# tviic2d4m register map
Vendor: Infineon Technologies; Series: TVIIC2D4M; File version: 1.0
CPU: CM7 r0p1, little endian, MPU, FPU, double-precision FPU, I-cache, D-cache, VTOR, ITCM, DTCM, 3 interrupt priority bits, 16 interrupts
Registers are 32-bit, read-write, reset 0x0 unless marked. A register's access mark holds for its fields unless they carry their own. Offsets are from the block's base; [hi:lo] are bit positions; lines under a group give offsets from that group; {n}, {i} and the like mark numbered series; <NAME> marks a mode.

## CXPI0 — CXPI
Base 0x40510000
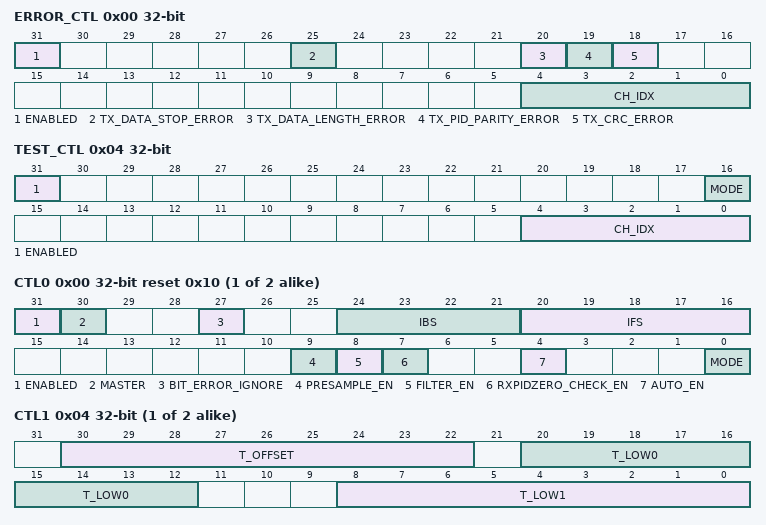
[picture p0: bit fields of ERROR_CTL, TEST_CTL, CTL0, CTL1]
0x00 ERROR_CTL — Error control
  [31] ENABLED — Error injection enable: '0': Disabled. '1': Enabled.
  [25] TX_DATA_STOP_ERROR — The data field STOP bits are inverted to '0'. At the receiver, this should result in INTR.RX_FRAME_ERROR activation. At the transmitter, this should result in INTR.TX_FRAME_ERROR activation.
  [20] TX_DATA_LENGTH_ERROR — The transmitter continues to send logical '0' (during IFS) after CRC field is transmitted. At the receiver, this should result in INTR.RX_DATA_LENGTH_ERROR activation. At the transmitter, this should result in INTR.TX_DATA_LENGTH_ERROR activation.
  [19] TX_PID_PARITY_ERROR — In cxpi mode, the PID parity bit P[1] is inverted from !(ID[5] ^ ID[4] ^ ID[3] ^ ID[1]) to (ID[5] ^ ID[4] ^ ID[3] ^ ID[1]). At the receiver, this should result in INTR.RX_HEADER_PARITY_ERROR activation.
  [18] TX_CRC_ERROR — The crc field is inverted. At the receiver, this should result in INTR.RX_CRC_ERROR activation.
  [4:0] CH_IDX — Specifies the channel index of the channel to which HW injected channel transmitter errors applies.
0x04 TEST_CTL — Test control
  [31] ENABLED — Test enable: '0': Disabled. Functional mode. - tx_in[CH_IDX] = IOSS cxpi_tx_in[CH_IDX]. - tx_in[CH_NR-1] = IOSS cxpi_tx_in[CH_NR-1]. - rx_in[CH_IDX] = IOSS cxpi_rx_in[CH_IDX]. - rx_in[CH_NR-1] = IOSS cxpi_rx_in[CH_NR-1]. - cxpi_tx_out[CH_IDX] = tx_out[CH_IDX]. - cxpi_tx_out[CH_NR-1] = tx_out[CH_NR-1]. '1': Enabled. Test mode, specific test mode is specified by MODE.
    0=FUNCTIONAL_MODE; 1=TEST_MODE
  [16] MODE — Test mode: '0': Partial disconnect from IOSS. This mode's isolation allows for device test without relying on an external cxpi transceiver. The IOSS 'tx' IO cell can be used to observe messages outside of the device. - tx_in[CH_IDX] = IOSS cxpi_tx_in[CH_IDX]. - tx_in[CH_NR-1] = IOSS cxpi_tx_in[CH_IDX]. - rx_in[CH_IDX] = IOSS cxpi_tx_in[CH_IDX]. - rx_in[CH_NR-1] = IOSS cxpi_tx_in[CH_IDX]. - cxpi_tx_out[CH_IDX] = tx_out[CH_IDX] & tx_out[CH_NR-1]. - cxpi_tx_out[CH_NR-1] = tx_out[CH_IDX] & tx_out[CH_NR-1]. '1': Full disconnect from IOSS (the IOSS/HSIOM should disconnect 'tx_out' from the 'tx' IO cell). This mode's isolation allows for device test without effecting an operational cxpi cluster. - tx_in[CH_IDX] = cxpi_tx_out[CH_IDX]. - tx_in[CH_NR-1] = cxpi_tx_out[CH_IDX]. - rx_in[CH_IDX] = cxpi_tx_out[CH_IDX]. - rx_in[CH_NR-1] = cxpi_tx_out[CH_IDX]. - cxpi_tx_out[CH_IDX] = tx_out[CH_IDX] & tx_out[CH_NR-1]. - cxpi_tx_out[CH_NR-1] = tx_out[CH_IDX] & tx_out[CH_NR-1].
    0=PARTIAL_DISCONNECT; 1=FULL_DISCONNECT
  [4:0] CH_IDX — Specifies the channel index of the channel to which test applies. The channel IO signals of channel indices CH_IDX and CH_NR-1 are connected as specified by MODE. CH_IDX should be in the range [0, CH_NR-2], as channel index CH_NR-1 is always involved in test and cannot be connected to itself. The test mode allows BOTH of the two connected channels to be tested. Note: this testing functionality simplifies SW development, but may also be used in the field to verify correct channel functionality.
{0x8000+0x100*i} CH[{i}] (i=0..1) group — CXPI channel structure
  0x00 CTL0 reset 0x10 — Control 0
    [31] ENABLED — Channel enable: '0': Disabled. If a channel is disabled, CMD, STATUS, INTR MMIO registers will have their fields reset to their default value. '1': Enabled.
      0=DISABLED; 1=ENABLED
    [30] MASTER — CXPI master mode. '0': Indicates CXPI as slave node. '1': Indicates CXPI as master node. This bit is only valid if ENABLED=1. SW needs to set only 1 node as master within the same CXPI cluster. SW needs to set this bit either at the same time as ENABLED or before ENABLED is set. If SW needs to change the controller to different mode, it needs to make sure that HW is quiescent before doing so.
      0=SLAVE_MODE; 1=MASTER_MODE
    [27] BIT_ERROR_IGNORE — Specifies behavior on a detected bit error during header or response transmission: '0': Message transfer is aborted. '1': Message transfer is NOT aborted. Note: This field does NOT effect the reporting of the bit error through INTR/STATUS.TX_BIT_ERROR; i.e. bit errors are always reported. Note: This field must not be set to '1' when it is NRZ mode. This is due to delay in transceiver will cause the transmitter behavior undefined when error occurs.
      0=ABORT_TX_MSG (Message transfer is aborted); 1=CONT_TX_MSG (Message transfer is NOT aborted)
    [24:21] IBS — Inter Byte Space in bit periods: '0' No offset. '1' 1 IBS is inserted per every byte frame. ... '9' 9 IBS are inserted per every byte frame. Values >9 are invalid per spec. This field is used to control number of IBS after every byte frame when transmitting message frame. Note that this field is the minimum IBS inserted for every byte frame as the SW may require some time to prepare the response when it receives the PID. When receiving, this field is ignored with the exception of receiving header and transmitting response. For receiving header and transmitting response, SW can enable IBS insertion by setting TIMEOUT_SEL=1/2 prior to setting CMD.RX_HEADER=1 and CMD.RX_RESPONSE=1. If the received header corresponds to transmit response, SW clears CMD.RX_RESPONSE =0 and sets TX FIFO and CMD.TX_RESPONSE=1. HW waits for minimum IBS before transmit response (if timeout has not occurred yet). It is prohibit to program IBS>TIMEOUT_LENGTH. This field should not be changed during inflight transaction including EOF.
    [20:16] IFS — Inter Frame Space in bit periods: '0'' Invalid. ... '10': 10 bit periods ... '31': 31 bit periods Values of <10 are not allowed. This field is used for transmission/reception for adding waiting inter frame space. Note that after a valid transaction (after CRC), HW waits for 10 bits as EOF. Hence, by setting CTL0.IFS=0xA means that HW will wait for 10bits before transmitting a new transaction (not including the EOF). Note: 0 is not allowed when IFS_WAIT=1. SW needs to ensure it has program valid values before it can set IFS_WAIT=1. If IFS_WAIT=1 after timeout occurs, the value of CTL0.IFS would need to consider the timeout count i.e. (IFS needed - CTL2.TIMEOUT_LENGTH-1) to get the total idle time. For example if TIMEOUT_LENGTH=9 and IFS needed is 20, then CTL0.IFS is set to 10.
    [9] PRESAMPLE_EN — Pre-sample enable for PWM mode. '0': Disbaled. '1': Enabled When sampling counter's value is greater than CTL1.T_LOW1, pre-sample FF will be set to '1' as long as detecting any '1' on 'cxpi_rx_in' and be cleared to '0' after sampling moment. At the sampling moment, if pre-sample FF or 'cxpi_rx_in' is '1', sample value will be '1', otherwise '0'.
    [8] FILTER_EN — RX filter enable (for 'cxpi_rx_in') '0': No filter '1': Median 3 (default value) operates on the last three 'cxpi_rx_in' values. The sequences '000', '001', '010', and '100' result in a filtered value '0'. The sequences '111', '110', '101', and '011' result in a filtered value '1'.
    [7] RXPIDZERO_CHECK_EN — Receive PID Zero Check Enable. 0 - No action if received PID[6:0] = 0 and PID[7]=1'b1. 1 - If received PID[6:0] = 0 and PID[7]=1'b1, HW (slave) does not clear CMD.RX_HEADER and will anticipate receiving header again (CMD.TX_HEADER=0). If CMD.TX_HEADER=1 in the same scenario, then HW (slave) clears CMD.RX_HEADER upon receiving the header follow by transmit PID. This mode is useful for case where polling method is used and CXPI controller is configured as slave. This would reduce dependency on SW to react to the header received within IBS=1.
    [4] AUTO_EN — CXPI transceiver auto enable: '0': Disabled. '1': Enabled. The TX_RX_STATUS.EN_OUT field is controlled by HW.
    [0] MODE — Mode of operation: '0': NRZ mode. '1': PWM mode.
      0=NRZ (NRZ mode); 1=PWM (PWM mode)
  0x04 CTL1 — Control 1
    [30:22] T_OFFSET — The value of offset that is used for sampling the 'rx'. The value of this counter is used in HW as below. - 0 : means 1 clock after detecting falling edge of 'rx' - 1 : means 2 clocks after detecting falling edge of 'rx' .. - 7 : means 8 clocks after detecting falling edge of 'rx' .. - 15 : means 16 clocks after detecting falling edge of 'rx' .. - 399 : means 400 clocks after detecting falling edge of 'rx' Any value above 399 is invalid.
    [20:12] T_LOW0 — Low count for logic 0. This is valid only for PWM mode. The count value here indicates the number of clocks per clk_cxpi_ch to drive a '0' at CXPI bus before releasing it to indicate a logical '0'. 0: means 1 clock. 1: means 2 clocks .. 15: means 16 clocks .. 399: means 400 clocks Any value above 399 is invalid. Note that for NRZ mode, this field is ignored. Note that this field is used for TX.
    [8:0] T_LOW1 — Low count for logic 1. This is valid only for PWM mode. For master node, The count value here indicates the number of clocks per clk_cxpi_ch to drive a '0' at CXPI bus before releasing it to indicate a logical '1'. For slave node and pre-sample enabled, the count value indicates the number of clocks per clk_cxpi_ch to disable pre-sampling. 0: means 1 clock. 1: means 2 clocks .. 15: means 16 clocks. .. 399: means 400 clocks. Any value above 399 is invalid. Note that for NRZ mode, this field is ignored. Note that it must be set less than CTL1.T_OFFSET for slave node if pre-sample mode enabled. Note that it is also effective for pre-sample mode of master node.
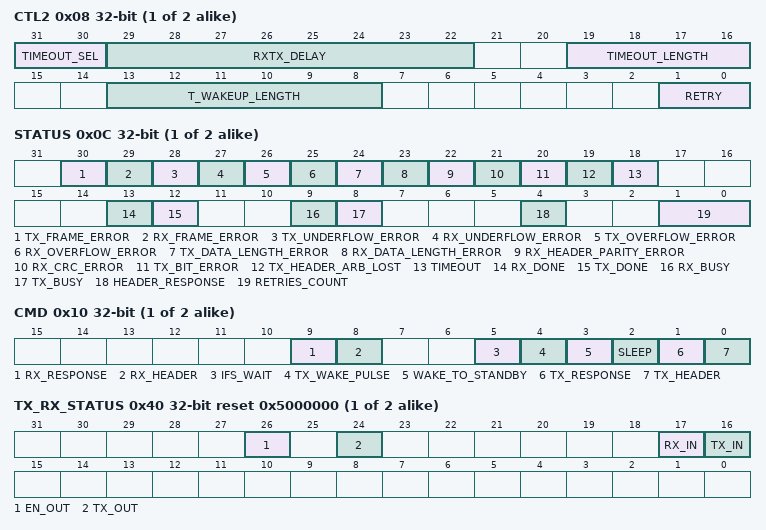
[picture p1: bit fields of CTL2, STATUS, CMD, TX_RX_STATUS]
  0x08 CTL2 — Control 2
    [31:30] TIMEOUT_SEL — Timeout Select. '0' - Timeout check is disabled. HW clears timeout counter. '1' - Timeout check is enabled and HW will refer to TIMEOUT_LENGTH as number of Tbits allowed between header and response. '2' - Timeout check is enabled to check header-header, header-response, and header-header-response within a message frame to be space within TIMEOUT_LENGTH bit time. '3' - invalid For '1', HW will restart/start timeout counter after transmitting/receiving header. HW will hold the counter if timeout until the next header is transmitted or received. Timeout will cause HW to stop transmission of the current message frame together with interrupt to SW. For receive, HW abort reception of the frame if timeout occurs while waiting for receiving response and notify SW with interrupt. For '2', HW will re-start/start timeout counter after receiving any frame bytes within a message frame. HW will hold the counter if timeout until the IFS. Timeout will cause HW to stop transmission of the current message frame and notify SW with interrupt. For receive, HW will abort reception of the message frame if timeout occurs while waiting for receiving response and notify SW with interrupt. For all cases, HW stops counting when it is out of a message frame such as IFS or CXPI bus IDLE. If the timeout counter > TIMEOUT_LENGTH, then it will set the INTR.TIMEOUT=1. Note that, TIMEOUT_SEL=1/2 also enables the count for IBS between receive header and transmit response on top of timeout check.
      0=TIMEOUT_DISABLED (Timeout check is disabled.); 1=TIMEOUT_CHECK_BTW_HDR_RSP (Timeout check is enabled and HW will refer to TIMEOUT_LENGHT as number of Tbits allowed between header and response.); 2=TIMEOUT_CHECK_BTW_HDR_HDR_RSP (Timeout check is enabled to check header-header, header-response, and header-header-response within a message frame to be space within TIMEOUT_LENGTH bit time.)
    [29:22] RXTX_DELAY — Insert addtional delay from the falling edge of RX to the falling edge of TX for slave node transmitting '0'. This is valid only for PWM mode. The count value here indicates the number of clocks per clk_cxpi_ch. 0: None 1: means 1 clock. 2: means 2 clocks. ... 255: means 255 clocks. Note it must be set less than CTL1.T_LOW0. Note make sure that the falling edge of tx_out is ahead of the rising edge of master node clock when CTL0.PRESAMPLE_EN=1.
    [19:16] TIMEOUT_LENGTH — Timeout Length (in Tbits). Specifies the number of Tbits to exceed timeout between frame bytes within a message frame. CXPI spec states that the maximum allowed inter byte space (IBS) is 9Tbits. This field is valid only when TIMEOUT_SEL=1/2. '0' - 1Tbit '1' - 2Tbits .. '9' - 10Tbits Values >9 is invalid per CXPI spec. Note for NRZ mode, although there are propagation delay from transceiver to CXPI controller, the delay is cancelled out as the timeout is compared on the RX (for transmit case, HW waits for the feedback on RX).
    [13:8] T_WAKEUP_LENGTH — Specifies the wake up pulse low period in Tbits that is transmitted during Standby mode. '0': 1 bit period '1': 2 bit period .. '49': 50 bit period Any value above 49 is invalid. This field is only valid if TX_WAKE_PULSE is set to 1.
    [1:0] RETRY — Number of retries after arbitration lost. '0': No retries. .. '3': 3 retries. HW will immediately retry after arbitration lost i.e. after the message frame that won the arbitration is complete and fulfilled IFS. If SW wants to manage the retransmission then SW can program RETRY =0. In this case, HW will not retry after arbitration lost and will set TX_HEADER_ARB_LOST bit. SW needs to trigger HW to resend by programming the CMD fields again.
  0x0C STATUS ro
    [30] TX_FRAME_ERROR — Copy of INTR.TX_FRAME_ERROR.
    [29] RX_FRAME_ERROR — Copy of INTR.RX_FRAME_ERROR.
    [28] TX_UNDERFLOW_ERROR — Copy of INTR.TX_UNDERFLOW_ERROR.
    [27] RX_UNDERFLOW_ERROR — Copy of INTR.RX_UNDERFLOW_ERROR.
    [26] TX_OVERFLOW_ERROR — Copy of INTR.TX_OVERFLOW_ERROR.
    [25] RX_OVERFLOW_ERROR — Copy of INTR.RX_OVERFLOW_ERROR.
    [24] TX_DATA_LENGTH_ERROR — Copy of INTR.TX_DATA_LENGTH_ERROR.
    [23] RX_DATA_LENGTH_ERROR — Copy of INTR.RX_DATA_LENGTH_ERROR.
    [22] RX_HEADER_PARITY_ERROR — Copy of INTR.RX_HEADER_PARITY_ERROR.
    [21] RX_CRC_ERROR — Copy of INTR.RX_CRC_ERROR.
    [20] TX_BIT_ERROR — Copy of INTR.TX_BIT_ERROR.
    [19] TX_HEADER_ARB_LOST — Copy of INTR.TX_HEADER_ARB_LOST
    [18] TIMEOUT — Copy of INTR.TIMEOUT
    [13] RX_DONE — Receiver done: - Set to '0' on the start of a new command. - Set to '1' on successful completion of the following commmand sequences: - RX_HEADER, RX_RESPONSE. - TX_HEADER, RX_RESPONSE.
    [12] TX_DONE — Transmitter done: - Set to '0' on the start of a new command. - Set to '1' on successful completion of the following command sequences: - TX_HEADER. - TX_HEADER, TX_RESPONSE. - RX_HEADER, TX_RESPONSE.
    [9] RX_BUSY — Receiver busy. - Set to '1' on the start of the following commands: RX_HEADER, RX_RESPONSE. - Set to '0' on successful completion of previous commands or when an error is detected.
    [8] TX_BUSY — Transmitter busy. - Set to '1' on the start of the following commands: TX_HEADER, TX_RESPONSE. - Set to '0' on successful completion of previous commands or when an error is detected.
    [4] HEADER_RESPONSE — Frame header/response identifier (only valid when TX_BUSY or RX_BUSY is '1') '0' - Frame header being transferred. '1' - Frame response being transferred.
    [1:0] RETRIES_COUNT — Retries count. The value reflects the number of retries that HW tries to transmit a header/response. HW will reset counter (either case below): 1. after successfully transmit the retry attempt 2. SW clears the CMD.TX_HEADER='0' 3. HW clearing CMD.TX_HEADER=0 due to errors (TX_BIT_ERROR, TX_HEADER_ARB_LOST, TX_OVERFLOW_ERROR, TX_UNDERFLOW_ERROR, TX_DATA_LENGTH_ERROR, and TX_FRAME_ERROR)
  0x10 CMD — Command
    [9] RX_RESPONSE — SW sets this field to '1' to receive a response. HW sets this field to '0' on successful completion of ANY of the legal command sequences (NOT set to '0' when an error is detected). -TX_HEADER, RX_RESPONSE -RX_HEADER, RX_RESPONSE SW can set this field to '1' to be conservative on receiving response i.e. IBS=0 whenever it is receiving PID. If the PID corresponds to transmit response, the SW can then clear this field to '0' and set TX_RESPONSE=1 to direct HW to send response. The response is received after CRC are received (INTR.RX_RESPONSE_DONE).
    [8] RX_HEADER — SW sets this field to '1' to receive a header. HW sets this field to '0' on successful completion of the ANY of the legal command sequences. (Not set to '0' when an error is detected). -RX_HEADER -RX_HEADER, TX_RESPONSE -RX_HEADER, RX_RESPONSE The above applies for cases of receiving PID without prior receiving PTYPE. The header is received when the PID field STOP bits are received (INTR.RX_HEADER_PID_DONE and INTR.RX_HEADER_DONE). Typically, a slave node SW sets both RX_HEADER and RX_RESPONSE to '1', anticipating a transfer of a response from the master node to this slave node. After receipt of the header PID/PTYPE field (INTR.RX_HEADER_PID_DONE is activated), the slave node may decide to set TX_RESPONSE to '1' (which has lower priority than RX_RESPONSE hence RX_RESPONSE need to be clear to '0' by SW) to transmit a response. Note that, for cases with RXPIDZERO_CHECK_EN=1 for slave in polling mode, RX_HEADER is cleared upon receiving PTYPE if the next course of action is to transmit PID. If the next course of action is to receive PID, then the RX_HEADER is cleared upon completion of response.
    [5] IFS_WAIT — SW sets this field to '1' to wait for IFS. HW clears this field to '0' after it detects logical '1' based on IFS. HW will keep this field to '1' if it detects logical '0' before fulfilling the number of logical '1' required. The intention of this bit is to provide capability for SW to direct HW to check bus idle-ness before transmitting. Without setting this bit before directing HW to send header, HW will not check bus idle before transmitting. Besides that, this bit will also provide SW an option to configure HW to wait for IFS before sending again PTYPE or PID to fulfill IFS if there is no response from other nodes. Note: SW needs to configure valid IFS values before setting IFS_WAIT=1.
    [4] TX_WAKE_PULSE — SW sets this field to '1' to direct HW to send wake up pulse. HW will transmit wake up pulse in Standby state only. HW will ignore this field when it's not in Standby state. '1' - HW will drive CXPI bus to low for period dictated by T_WAKEUP_LENGTH. '0:'- No wake up pulse HW clears this field to '0' after it transmit the pulse per T_WAKEUP_LENGTH. For the case where more than 1 wake pulses are required, SW is expected to set this field to '1' again (after this field is cleared to '0') per the number of times the wake pulse is required.
    [3] WAKE_TO_STANDBY — SW sets this field to '1' to direct HW to wake up from Sleep mode to Standby mode. SW clears this field to '0' from '1' when it wants to direct HW from Standby to Normal mode. HW clears this field to '0' when it is in Normal mode or back to Sleep mode from Standby mode. For the case of CXPI master mode, HW will move its power mode from Sleep->Standby when this field is set to '1'. When SW clears this field is from '1' to '0' in Standby mode, HW will move to Normal mode while HW starts transmitting clock. To transmit wake pulse, SW need to program TX_WAKE_PULSE accordingly in Standby mode before entering Normal. For the case of CXPI slave mode and PWM mode, HW will move power mode from Sleep->Standby when this field is set to '1'. HW will wait for detection of clock before moving from Standby->Normal. SW clearing this field to '0' will have no effect. For the case of CXPI slave mode and NRZ mode, HW will move power mode from Sleep->Standby when this field is set to '1'. HW needs to be directed by SW by clearing this field to '0' to move from Standby->Normal after SW has detected clock through another IP (e.g. MXTCPWM).
    [2] SLEEP write-1-sets — SW sets this field to '1' to direct HW to sleep mode. HW transits from Normal to Sleep upon SLEEP=1 and both TX and RX is idle. HW sets this field to '0' when it is in Sleep mode. Note that, SW needs to manage the entry to sleep mode by checking the conditions are met before initiating sleep mode e.g. all slave nodes supports sleep and on transmitting sleep frames to indicate sleep to all slave nodes.SW shall not program SLEEP=1 when HW is executing TX_WAKEUP_PULSE command. If SW programs SLEEP=1 during HW executing TX_WAKEUP_PULSE command, it will cause HW to abruptly stop transmitting wakeup pulse as below: 1. HW not clearing TX_WAKEUP_PULSE 2. HW not setting TX_WAKEUP_DONE 3. HW outputting TX_OUT=0.
    [1] TX_RESPONSE — SW sets this field to '1' to transmit a response. HW sets this field to '0' on successful completion of ANY of the legal command sequences (also set to '0' when an error is detected). - TX_HEADER, TX_RESPONSE. - RX_HEADER, TX_RESPONSE. SW can also clear this field to '0' if SW wants to cancel the TX_RESPONSE. The response is transmitted when the CRC are transmitted (INTR.TX_RESPONSE_DONE).
    [0] TX_HEADER — SW sets this field to '1' to transmit a header. HW sets this field to '0' on successful completion of ANY of the following legal command sequences (also set to '0' when an error (such as bit error if bit_ignore=0, arbitration loss, tx data length error. For timeout please refer to SAS) is detected): - TX_HEADER - TX_HEADER, TX_RESPONSE. - TX_HEADER, RX_RESPONSE. The above is for transmission of PID without prior transmission of PTYPE. The header is transmitted when the PID field STOP bits are transmitted (INTR.TX_HEADER_DONE). HW sets this field to '1', when the 'tr_cmd_tx_header' input trigger is activated. This allows for time triggered CXPI message transfer. HW driven time triggered transfer eliminates the jitter that is typically associated with SW driven transfer. SW clears this field to '0', when it wants to cancel a pending request. Note that if SW clears this field to '0' while HW is already in the middle of the request, then the cancel will be ignored. The cancel request can happen when HW is pending a retry when it is still servicing the current transaction. Or the cancel request can occur when HW is checking IFS/bus idle-ness. Note that if PTYPE (TX_HEADER) is transmitted follow by receive response (RX_RESPONSE) or no response, HW clears TX_HEADER right after transmitting PTYPE.
  0x40 TX_RX_STATUS reset 0x5000000 (reset mask 0x5000000)
    [26] EN_OUT — CXPI transceiver enable ('en_out', 'cxpi_en_out'). This field controls the enable (or low active sleep enable) of the external transceiver: '0': Disabled. '1': Enabled. If CTL0.AUTO_EN is '0', SW controls this field to enable the external transceiver. If CTL0.AUTO_EN is '1', HW controls this field to enable the external transceiver: - HW sets this field to '1' when it is out of Sleep state. If it moves to Sleep state, HW will clear this field to '0'.
    [24] TX_OUT ro — CXPI transmitter output ('tx_out', 'cxpi_tx_out').
    [17] RX_IN ro — CXPI receiver input ('rx_in', 'cxpi_rx_in' in functional mode).
    [16] TX_IN ro — CXPI transmitter input ('tx_in', 'cxpi_tx_in' in functional mode). TX_IN and RX_IN can be used to determine a wakeup source. Note that wakeup source detection relies on the external transceiver functionality.
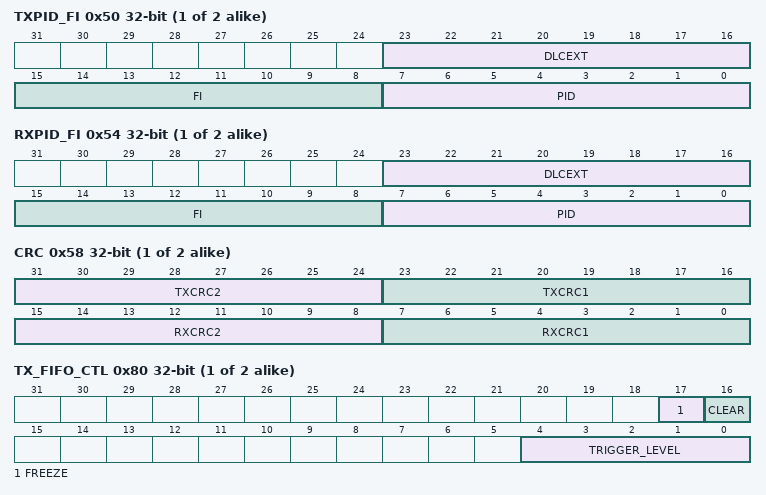
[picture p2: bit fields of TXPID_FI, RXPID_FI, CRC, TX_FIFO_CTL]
  0x50 TXPID_FI reset not defined — TXPID and Frame Information
    [23:16] DLCEXT — Data Length Count Extension. This field is intended for payload of more than 12B. This field is only valid if DLC=4'b1111 (FI[7:4]). The value specified in this field will be the new payload size. Valid values are 0-255.
    [15:8] FI — Frame Information. This is the byte that will be transmitted as Frame Information. Per CXPI spec, FI[7:4] denotes the data length count (DLC). FI[3:2] denotes Network Management. Bit[3] - wakeup.ind Bit[2] - sleep.ind FI[1:0] denotes CT. Please program to 2'b11 if no support of counter.
    [7:0] PID — Header protected identifier (PID). - Bits 6 downto 0: frame identifier ID[6:0]. - Bits 7: is odd parity bit. - PID[7] = ! (ID[6] ^ ID[5] ^ ID[4] ^ ID[3] ^ ID[2] ^ ID[1] ^ ID[0]) Software does not need to program the parity bit i.e. bit[7]. HW will calculate the odd parity bit and ignore the bit[7] if SW occupies this bit. Transmission: To be transmitted PID field. HW will ignore bit[7] and compute the parity bit based on bits[6:0] Note that, this field can be use by SW to send PType byte as the HW handles both PID and PType the same way. The frame type would occupy bit[6:0] and the odd parity will be calculated by the HW.
  0x54 RXPID_FI ro reset not defined — RXPID and Frame Information
    [23:16] DLCEXT — Data Length Count Extension. This field is intended for payload of more than 12B. This field is only valid if DLC=4'b1111 (FI[15:12]). The value specified in this field will be the new payload size. Valid values are 0-255.
    [15:8] FI — Frame Information. This is the byte that is received as Frame Information. Per CXPI spec, FI[7:4] denotes the data length count (DLC). FI[3:2] denotes Network Management. Bit[3] - wakeup.ind Bit[2] - sleep.ind FI[1:0] denotes CT.
    [7:0] PID — Header protected identifier (PID). - Bits 6 downto 0: frame identifier ID[6:0]. - Bits 7: is odd parity bit. - PID[7] = ! (ID[6] ^ ID[5] ^ ID[4] ^ ID[3] ^ ID[2] ^ ID[1] ^ ID[0]) Reception: Received PID field. SW uses the PID field to determine how to handle the response for a received frame header: TX_RESPONSE or RX_RESPONSE. Note that, this field can be use by SW to check PType byte as the HW handles both PID and PType the same way. The frame type would occupy bit[6:0] and bit[7] is the parity bit of the frame type. This parity bit is send by the transmitting node.
  0x58 CRC ro reset not defined
    [31:24] TXCRC2 — CRC second byte of CRC16. This is valid only for Long frames. HW will load this field with second byte of CRC for transmit.
    [23:16] TXCRC1 — CRC first byte for both CRC8 and CRC16. This is valid for both Normal frame and Long frame. HW will load this field with first byte of CRC for transmit.
    [15:8] RXCRC2 — CRC second byte of CRC16. This is valid only for Long frames. HW will load this field with second byte of CRC upon receiving it.
    [7:0] RXCRC1 — CRC first byte for both CRC8 and CRC16. This is valid for both Normal frame and Long frame. HW will load this field with first byte of CRC upon receiving it.
  0x80 TX_FIFO_CTL — TX FIFO control
    [17] FREEZE — Freeze functionality: '0': HW uses TX FIFO data and pops the data from the TX FIFO for every HW read. '1': HW read from TX FIFO does not pop the data from the TX FIFO. Note: Freeze functionality is for debug purpose only.
    [16] CLEAR — This is a synchronous clear signal to the TX FIFO. When '1', the TX FIFO content are cleared. If a quick clear is required, the field should be set to '1' and followed by '0'. If a clear is required for an extended time, the field should be set to 1 during the complete time.
    [4:0] TRIGGER_LEVEL — Trigger level. When the TX FIFO has less entries than the number of this field, a transmitter trigger event is generated: -INTR.TX_FIFO_TRIGGER = (#FIFO entries < TRIGGER_LEVEL)
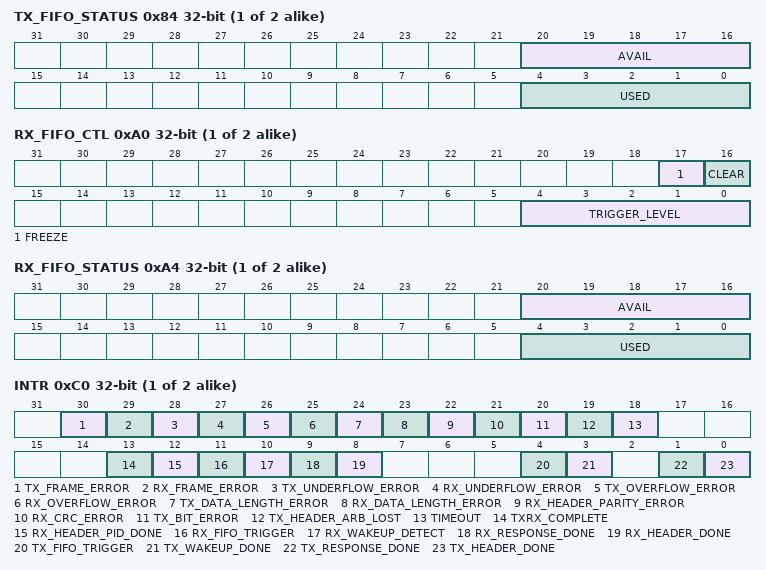
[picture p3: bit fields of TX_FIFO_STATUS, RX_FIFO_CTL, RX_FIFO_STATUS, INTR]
  0x84 TX_FIFO_STATUS ro (reset mask 0x1F)
    [20:16] AVAIL — TX FIFO Avail 0-No available slot in TX FIFO 1-1 available slot in TX FIFO. 2-2 available slot in TX FIFO. .. 16-16 available slot in TX FIFO. Note that the Fifo Width is 1Byte and each slot in this context is 1 depth of the Fifo. The number of bytes are determine through the number of data bytes in a message frame. (TXPID_FI.FI/TXPID_FI.DLCEXT)
    [4:0] USED — Number of used/occupied entries in the TX FIFO. The field value is in the range [0, 16]. When '0', the TX FIFO is empty. When '16', the TX FIFO is full.
  0x88 TX_FIFO_WR wo — TX FIFO write
    [7:0] DATA — Transmit Data field. Transmission: To be transmitted data field. SW provides data field. HW shadows over the write data to TX FIFO after SW performs a write to this field. HW shadows the whole 8 bits to the TX FIFO and relies on the TXPID_FI.FI/TXPID_FI.DCLEXT to determine the number of bytes. SW needs to ensure that TX FIFO is not overwritten before the content is consumed by HW by checking TX_FIFO_STATUS.AVAIL. Otherwise, the previous content would be overwritten and resulting in TX FIFO's overflow error (INTR.TX_OVERFLOW_ERROR).
  0xA0 RX_FIFO_CTL — RX FIFO control
    [17] FREEZE — Freeze functionality: '0': HW writes to RX FIFO and push the data to RX FIFO. '1': HW write to RX FIFO does not push the data to the RX FIFO. Note: Freeze functionality is for debug purpose only.
    [16] CLEAR — When '1', the RX FIFO content are popped. If a quick clear is required, the field should be set to '1' and followed by '0'. If a clear is required for an extended time, the field should be set to 1 during the complete time.
    [4:0] TRIGGER_LEVEL — Trigger level. When RX FIFO has more entries than the number of this field, a receiver trigger event is generated. - INTR_RX.FIFO_TRIGGER = (#FIFO entries > TRIGGER_LEVEL)
  0xA4 RX_FIFO_STATUS ro (reset mask 0x1F)
    [20:16] AVAIL — RX FIFO avail 0-No content in RX FIFO 1-1 available content in RX FIFO. 2-2 available content in RX FIFO. .. 16-16 available content in RX FIFO. Note that the Fifo Width is 1Byte and each content in this context means 1 fifo slot. The number of bytes in each slot are determine through the number of data bytes in a message frame. (RXPID_FI.FI/RXPID_FI.DLCEXT)
    [4:0] USED — Number of used/occupied entries in the RX FIFO. The field value is in the range [0, 16]. When '0', the RX FIFO is empty. When '16', the RX FIFO is full.
  0xA8 RX_FIFO_RD ro reset not defined — RX FIFO read
    [7:0] DATA — Received Data field. Software uses this data field. HW shadows the first content of the RX FIFO to this field. Software reading this field will remove the content from the RX FIFO and the next content of the RX FIFO will be shadowed over to this field. This field is 8bits and reflects the width of the RX FIFO. Software needs to rely on the RXPID_FI.FI/RXPID_FI.DLCEXT fields to determine number of bytes. Note that, during debug, a read from test controller would not remove/destory the content. Software needs to ensure it does not read from this field if there is no available content (from RX_FIFO_STATUS.USED). Otherwise, the content is undefined and it would result in RX FIFO underflow error. (INTR.RX_UNDERFLOW_ERROR).
  0xAC RX_FIFO_RD_SILENT ro reset not defined — RX FIFO silent read
    [7:0] DATA — Data read from the RX FIFO. Reading data from this field would not pop the data from RX FIFO. This register is for debug purpose.
  0xC0 INTR — Interrupt
    [30] TX_FRAME_ERROR write-1-clears — HW sets this field to '1', when the stop bit of a byte frame is incorrect. This error would be a subset of TX_BIT_ERROR and also subjected to BIT_ERROR_IGNORE field. Note: The ongoing message transfer is aborted (RX_HEADER_DONE and INTR.TX_RESPONSE_DONE are NOT activated. INTR.TX_HEADER_DONE is NOT activated if frame error occurs during the transmission of header byte) and the TX_HEADER and TX_RESPONSE commands are set to '0'. Note: When CTL0.BIT_ERROR_IGNORE is '0', the ongoing message transfer is aborted (INTR.TX_RESPONSE_DONE is NOT activated. INTR.TX_HEADER_DONE is NOT activated if frame error occurs during the transmission of header byte) and the TX_HEADER and TX_RESPONSE commands are set to '0'. When CTL0.BIT_ERROR_IGNORE is '1', the ongoing message transfer would be transferred.
    [29] RX_FRAME_ERROR write-1-clears — HW sets this field to '1', when the stop bit of a byte frame is incorrect. Note: The ongoing message transfer is aborted (INTR.RX_RESPONSE_DONE is NOT activated and the INTR.RX_HEADER_DONE is NOT activated if the frame error occurs during header byte or if frame error occurs during response byte (if the HEADER and RESPONSE commands are set together)).
    [28] TX_UNDERFLOW_ERROR write-1-clears — HW sets this field to '1', when TX FIFO is empty and HW reads from it. Note: The ongoing message transfer will continue when this error happens however, data transferred at CXPI will be bogus and HW will invert the CRC to invalidate the message at the receiving node. TX_HEADER and TX_RESPONSE commands are set to '0'.
    [27] RX_UNDERFLOW_ERROR write-1-clears — HW sets this field to '1', when RX FIFO is empty and SW reads from it. Note: Upon this error, SW should discard the RX data in RX FIFO.
    [26] TX_OVERFLOW_ERROR write-1-clears — HW sets this field to '1', when the TX data is overwritten by SW before the HW reads from it to transmit to CXPI bus. Note: The ongoing message transfer will continue when this error happens however, data transferred at CXPI bus will be bogus and HW will invert the CRC to invalidate the message at the receiving node. TX_HEADER and TX_RESPONSE commands are set to '0'.
    [25] RX_OVERFLOW_ERROR write-1-clears — HW sets this field to '1', when the RX data is overwritten by HW before the SW reads from it. In CXPI spec, this error is denoted as overrun error. Note: Upon this error, SW should discard the RX data in RX FIFO.
    [24] TX_DATA_LENGTH_ERROR write-1-clears — HW sets this field to '1, when the transmit message frame's data fields are more than the value specified in DLC (for normal frame) or DLCEXT (for long frame) i.e. after transmitting CRC(s) byte, HW is receiving logical '0' during EOF. Note: HW will still set TX_RESPONSE_DONE and the TX_HEADER and TX_RESPONSE commands are set to '0'.
    [23] RX_DATA_LENGTH_ERROR write-1-clears — HW sets this field to '1, when the received message frame's data fields are more than the value specified in DLC (for normal frame) or DLCEXT (for long frame) i.e. after receiving CRC byte(s), HW is receiving logical '0' during EOF. For the case of receiving data length less than DLC/DLCEXT, HW will also set this field to '1'. This is the case where IBS>9 before the number of data reaches data length, then HW will report as data length error. HW starts checking after frame information byte. Note: SW needs to handle the message transfer i.e. discard or flush out. HW will still set the RX_RESPONSE_DONE.
    [22] RX_HEADER_PARITY_ERROR write-1-clears — HW sets this field to '1', when the received PID field or PType field has a parity error. Note: The ongoing message transfer is aborted (INTR.RX_HEADER_PID_DONE is NOT activated).
    [21] RX_CRC_ERROR write-1-clears — HW sets this field to '1', when received CRC is not matching with the compute CRC from header and response. Note: The ongoing message transfer is aborted (INTR.RX_RESPONSE_DONE is NOT activated).
    [20] TX_BIT_ERROR write-1-clears — HW sets this field to '1', when a transmitted 'cxpi_tx_out' value does NOT match a received 'cxpi_rx_in' value. The match is performed for the PID fields or PType (for the START bit and STOP bit only) and for the rest of the response i.e. frame information fields, data fields and the crc field (for the START bit, DATA bits, and STOP bits). Note: When CTL0.BIT_ERROR_IGNORE is '0', the ongoing message transfer is aborted (INTR.TX_RESPONSE_DONE is NOT activated. INTR.TX_HEADER_DONE is NOT activated if bit error occurs during the transmission of header byte) and the TX_HEADER and TX_RESPONSE commands are set to '0'. When CTL0.BIT_ERROR_IGNORE is '1', the ongoing message transfer would be transferred.
    [19] TX_HEADER_ARB_LOST write-1-clears — HW sets this field to '1', when it detects arbitration lost after the number of retries has exceed the maximum allowed retries. Note: The ongoing message transfer is aborted (INTR.TX_HEADER_DONE and INTR.TX_RESPONSE_DONE is NOT activated and the TX_HEADER and TX_RESPONSE command is cleared to 0).
    [18] TIMEOUT write-1-clears — HW sets this field to '1', when the transmitted/received bytes space within a message frame is > TIMEOUT_LENGTH. SW needs to set TIMEOUT_SEL=0 before clearing TIMEOUT=0 to ensure HW does not immediately sets back the interrupt.
    [13] TXRX_COMPLETE write-1-clears — HW sets this field to '1', when message frame ends after EOF is completed and TX/RX_DATA_LENGTH_ERROR=0.
    [12] RX_HEADER_PID_DONE write-1-clears — HW sets this field to '1', when RX header (PID/PTYPE field) is received.
    [11] RX_FIFO_TRIGGER write-1-clears — HW sets this field to '1', when RX trigger is generated (#used RX FIFO > TRIGGER_LEVEL).
    [10] RX_WAKEUP_DETECT write-1-clears — HW sets this field to '1', when RX fall is detected in Sleep mode.
    [9] RX_RESPONSE_DONE write-1-clears — HW sets this field to '1', when a frame response (frame information fields, data fields, and crc field) is received (the CMD.RX_RESPONSE is completed).
    [8] RX_HEADER_DONE write-1-clears — HW sets this field to '1', when a frame header (PID field or PType field) is received (the CMD.RX_HEADER is completed). Specifically: - When followed by CMD.TX_RESPONSE or CMD.RX_RESPONSE, this field is set to '1' after completion of the message frame transfer. - When not followed by a response command, this field is set to '1' after completion of the header transfer if RXPIDZERO_CHECK_EN=1 and header received is PID. If RXPIDZERO_CHECK_EN=0 and response commands are not set, HW will set this field to '1' after receiving PID or PTYPE.
    [4] TX_FIFO_TRIGGER write-1-clears — HW sets this field to '1', when TX trigger is generated (#used TX FIFO < TRIGGER_LEVEL).
    [3] TX_WAKEUP_DONE write-1-clears — HW sets this field to '1', when a wakeup signal is transmitted (per CTL2.T_WAKEUP_LENGTH). This interrupt cause is activated on a transition from dominant/'0' state to recessive/'1' state; i.e. at the end of the wakeup signal.
    [1] TX_RESPONSE_DONE write-1-clears — HW sets this field to '1', when a frame response (frame information fields, data fields, and crc field) is transmitted (the CMD.TX_RESPONSE is completed).
    [0] TX_HEADER_DONE write-1-clears — HW sets this field to '1', when a frame header (PID field or PType field) is transmitted (the CMD.TX_HEADER is completed).
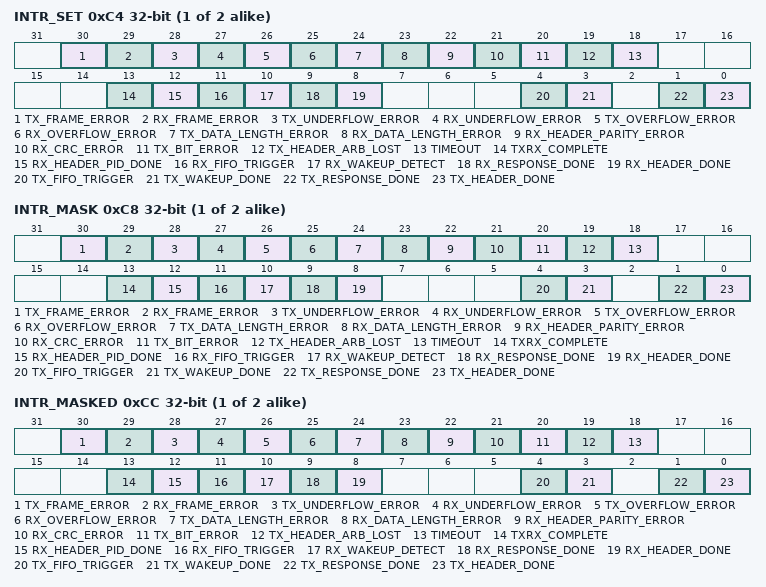
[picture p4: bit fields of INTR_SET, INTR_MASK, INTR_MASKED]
  0xC4 INTR_SET — Interrupt set
    [30] TX_FRAME_ERROR write-1-sets — Write INTR_SET field with '1' to set corresponding INTR field (a write of '0' has no effect).
    [29] RX_FRAME_ERROR write-1-sets — Write INTR_SET field with '1' to set corresponding INTR field (a write of '0' has no effect).
    [28] TX_UNDERFLOW_ERROR write-1-sets — Write INTR_SET field with '1' to set corresponding INTR field (a write of '0' has no effect).
    [27] RX_UNDERFLOW_ERROR write-1-sets — Write INTR_SET field with '1' to set corresponding INTR field (a write of '0' has no effect).
    [26] TX_OVERFLOW_ERROR write-1-sets — Write INTR_SET field with '1' to set corresponding INTR field (a write of '0' has no effect).
    [25] RX_OVERFLOW_ERROR write-1-sets — Write INTR_SET field with '1' to set corresponding INTR field (a write of '0' has no effect).
    [24] TX_DATA_LENGTH_ERROR write-1-sets — Write INTR_SET field with '1' to set corresponding INTR field (a write of '0' has no effect).
    [23] RX_DATA_LENGTH_ERROR write-1-sets — Write INTR_SET field with '1' to set corresponding INTR field (a write of '0' has no effect).
    [22] RX_HEADER_PARITY_ERROR write-1-sets — Write INTR_SET field with '1' to set corresponding INTR field (a write of '0' has no effect).
    [21] RX_CRC_ERROR write-1-sets — Write INTR_SET field with '1' to set corresponding INTR field (a write of '0' has no effect).
    [20] TX_BIT_ERROR write-1-sets — Write INTR_SET field with '1' to set corresponding INTR field (a write of '0' has no effect).
    [19] TX_HEADER_ARB_LOST write-1-sets — Write INTR_SET field with '1' to set corresponding INTR field (a write of '0' has no effect).
    [18] TIMEOUT write-1-sets — Write INTR_SET field with '1' to set corresponding INTR field (a write of '0' has no effect).
    [13] TXRX_COMPLETE write-1-sets — Write INTR_SET field with '1' to set corresponding INTR field (a write of '0' has no effect).
    [12] RX_HEADER_PID_DONE write-1-sets — Write INTR_SET field with '1' to set corresponding INTR field (a write of '0' has no effect).
    [11] RX_FIFO_TRIGGER write-1-sets — Write INTR_SET field with '1' to set corresponding INTR field (a write of '0' has no effect).
    [10] RX_WAKEUP_DETECT write-1-sets — Write INTR_SET field with '1' to set corresponding INTR field (a write of '0' has no effect).
    [9] RX_RESPONSE_DONE write-1-sets — Write INTR_SET field with '1' to set corresponding INTR field (a write of '0' has no effect).
    [8] RX_HEADER_DONE write-1-sets — Write INTR_SET field with '1' to set corresponding INTR field (a write of '0' has no effect).
    [4] TX_FIFO_TRIGGER write-1-sets — Write INTR_SET field with '1' to set corresponding INTR field (a write of '0' has no effect).
    [3] TX_WAKEUP_DONE write-1-sets — Write INTR_SET field with '1' to set corresponding INTR field (a write of '0' has no effect).
    [1] TX_RESPONSE_DONE write-1-sets — Write INTR_SET field with '1' to set corresponding INTR field (a write of '0' has no effect).
    [0] TX_HEADER_DONE write-1-sets — Write INTR_SET field with '1' to set corresponding INTR field (a write of '0' has no effect).
  0xC8 INTR_MASK — Interrupt mask
    [30] TX_FRAME_ERROR — Mask for corresponding field in INTR register.
    [29] RX_FRAME_ERROR — Mask for corresponding field in INTR register.
    [28] TX_UNDERFLOW_ERROR — Mask for corresponding field in INTR register.
    [27] RX_UNDERFLOW_ERROR — Mask for corresponding field in INTR register.
    [26] TX_OVERFLOW_ERROR — Mask for corresponding field in INTR register.
    [25] RX_OVERFLOW_ERROR — Mask for corresponding field in INTR register.
    [24] TX_DATA_LENGTH_ERROR — Mask for corresponding field in INTR register.
    [23] RX_DATA_LENGTH_ERROR — Mask for corresponding field in INTR register.
    [22] RX_HEADER_PARITY_ERROR — Mask for corresponding field in INTR register.
    [21] RX_CRC_ERROR — Mask for corresponding field in INTR register.
    [20] TX_BIT_ERROR — Mask for corresponding field in INTR register.
    [19] TX_HEADER_ARB_LOST — Mask for corresponding field in INTR register.
    [18] TIMEOUT — Mask for corresponding field in INTR register.
    [13] TXRX_COMPLETE — Mask for corresponding field in INTR register.
    [12] RX_HEADER_PID_DONE — Mask for corresponding field in INTR register.
    [11] RX_FIFO_TRIGGER — Mask for corresponding field in INTR register.
    [10] RX_WAKEUP_DETECT — Mask for corresponding field in INTR register.
    [9] RX_RESPONSE_DONE — Mask for corresponding field in INTR register.
    [8] RX_HEADER_DONE — Mask for corresponding field in INTR register.
    [4] TX_FIFO_TRIGGER — Mask for corresponding field in INTR register.
    [3] TX_WAKEUP_DONE — Mask for corresponding field in INTR register.
    [1] TX_RESPONSE_DONE — Mask for corresponding field in INTR register.
    [0] TX_HEADER_DONE — Mask for corresponding field in INTR register.
  0xCC INTR_MASKED ro — Interrupt masked
    [30] TX_FRAME_ERROR — Logical AND of corresponding INTR and INTR_MASK fields.
    [29] RX_FRAME_ERROR — Logical AND of corresponding INTR and INTR_MASK fields.
    [28] TX_UNDERFLOW_ERROR — Logical AND of corresponding INTR and INTR_MASK fields.
    [27] RX_UNDERFLOW_ERROR — Logical AND of corresponding INTR and INTR_MASK fields.
    [26] TX_OVERFLOW_ERROR — Logical AND of corresponding INTR and INTR_MASK fields.
    [25] RX_OVERFLOW_ERROR — Logical AND of corresponding INTR and INTR_MASK fields.
    [24] TX_DATA_LENGTH_ERROR — Logical AND of corresponding INTR and INTR_MASK fields.
    [23] RX_DATA_LENGTH_ERROR — Logical AND of corresponding INTR and INTR_MASK fields.
    [22] RX_HEADER_PARITY_ERROR — Logical AND of corresponding INTR and INTR_MASK fields.
    [21] RX_CRC_ERROR — Logical AND of corresponding INTR and INTR_MASK fields.
    [20] TX_BIT_ERROR — Logical AND of corresponding INTR and INTR_MASK fields.
    [19] TX_HEADER_ARB_LOST — Logical AND of corresponding INTR and INTR_MASK fields.
    [18] TIMEOUT — Logical AND of corresponding INTR and INTR_MASK fields.
    [13] TXRX_COMPLETE — Logical AND of corresponding INTR and INTR_MASK fields.
    [12] RX_HEADER_PID_DONE — Logical AND of corresponding INTR and INTR_MASK fields.
    [11] RX_FIFO_TRIGGER — Logical AND of corresponding INTR and INTR_MASK fields.
    [10] RX_WAKEUP_DETECT — Logical AND of corresponding INTR and INTR_MASK fields.
    [9] RX_RESPONSE_DONE — Logical AND of corresponding INTR and INTR_MASK fields.
    [8] RX_HEADER_DONE — Logical AND of corresponding INTR and INTR_MASK fields.
    [4] TX_FIFO_TRIGGER — Logical AND of corresponding INTR and INTR_MASK fields.
    [3] TX_WAKEUP_DONE — Logical AND of corresponding INTR and INTR_MASK fields.
    [1] TX_RESPONSE_DONE — Logical AND of corresponding INTR and INTR_MASK fields.
    [0] TX_HEADER_DONE — Logical AND of corresponding INTR and INTR_MASK fields.
